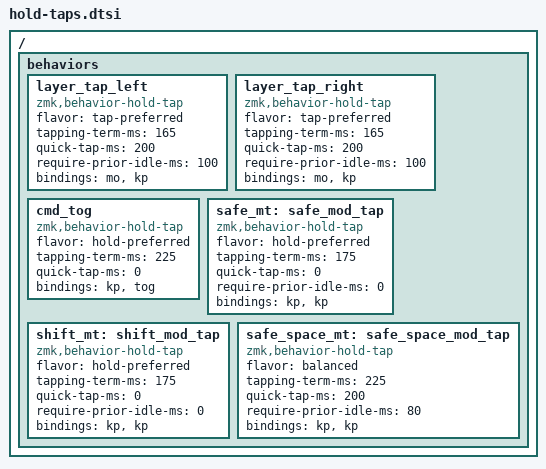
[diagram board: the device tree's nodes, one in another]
/*
 * Simulator copies of the production hold-taps. check-test-behaviors.py checks
 * every property against config/tomahawk56.keymap before tests can run.
 */
#include <behaviors.dtsi>
#include <dt-bindings/zmk/keys.h>
#include <dt-bindings/zmk/kscan_mock.h>

/ {
    behaviors {
        layer_tap_left: layer_tap_left {
            compatible = "zmk,behavior-hold-tap";
            #binding-cells = <2>;
            flavor = "tap-preferred";
            tapping-term-ms = <165>;
            quick-tap-ms = <200>;
            require-prior-idle-ms = <100>;
            bindings = <&mo>, <&kp>;
        };
        layer_tap_right: layer_tap_right {
            compatible = "zmk,behavior-hold-tap";
            #binding-cells = <2>;
            flavor = "tap-preferred";
            tapping-term-ms = <165>;
            quick-tap-ms = <200>;
            require-prior-idle-ms = <100>;
            bindings = <&mo>, <&kp>;
        };
        cmd_tog: cmd_tog {
            compatible = "zmk,behavior-hold-tap";
            #binding-cells = <2>;
            flavor = "hold-preferred";
            tapping-term-ms = <225>;
            quick-tap-ms = <0>;
            bindings = <&kp>, <&tog>;
        };
        safe_mt: safe_mod_tap {
            compatible = "zmk,behavior-hold-tap";
            #binding-cells = <2>;
            flavor = "hold-preferred";
            tapping-term-ms = <175>;
            quick-tap-ms = <0>;
            require-prior-idle-ms = <0>;
            bindings = <&kp>, <&kp>;
        };
        shift_mt: shift_mod_tap {
            compatible = "zmk,behavior-hold-tap";
            #binding-cells = <2>;
            flavor = "hold-preferred";
            tapping-term-ms = <175>;
            quick-tap-ms = <0>;
            require-prior-idle-ms = <0>;
            bindings = <&kp>, <&kp>;
        };
        safe_space_mt: safe_space_mod_tap {
            compatible = "zmk,behavior-hold-tap";
            #binding-cells = <2>;
            flavor = "balanced";
            tapping-term-ms = <225>;
            quick-tap-ms = <200>;
            require-prior-idle-ms = <80>;
            bindings = <&kp>, <&kp>;
        };
    };
};
